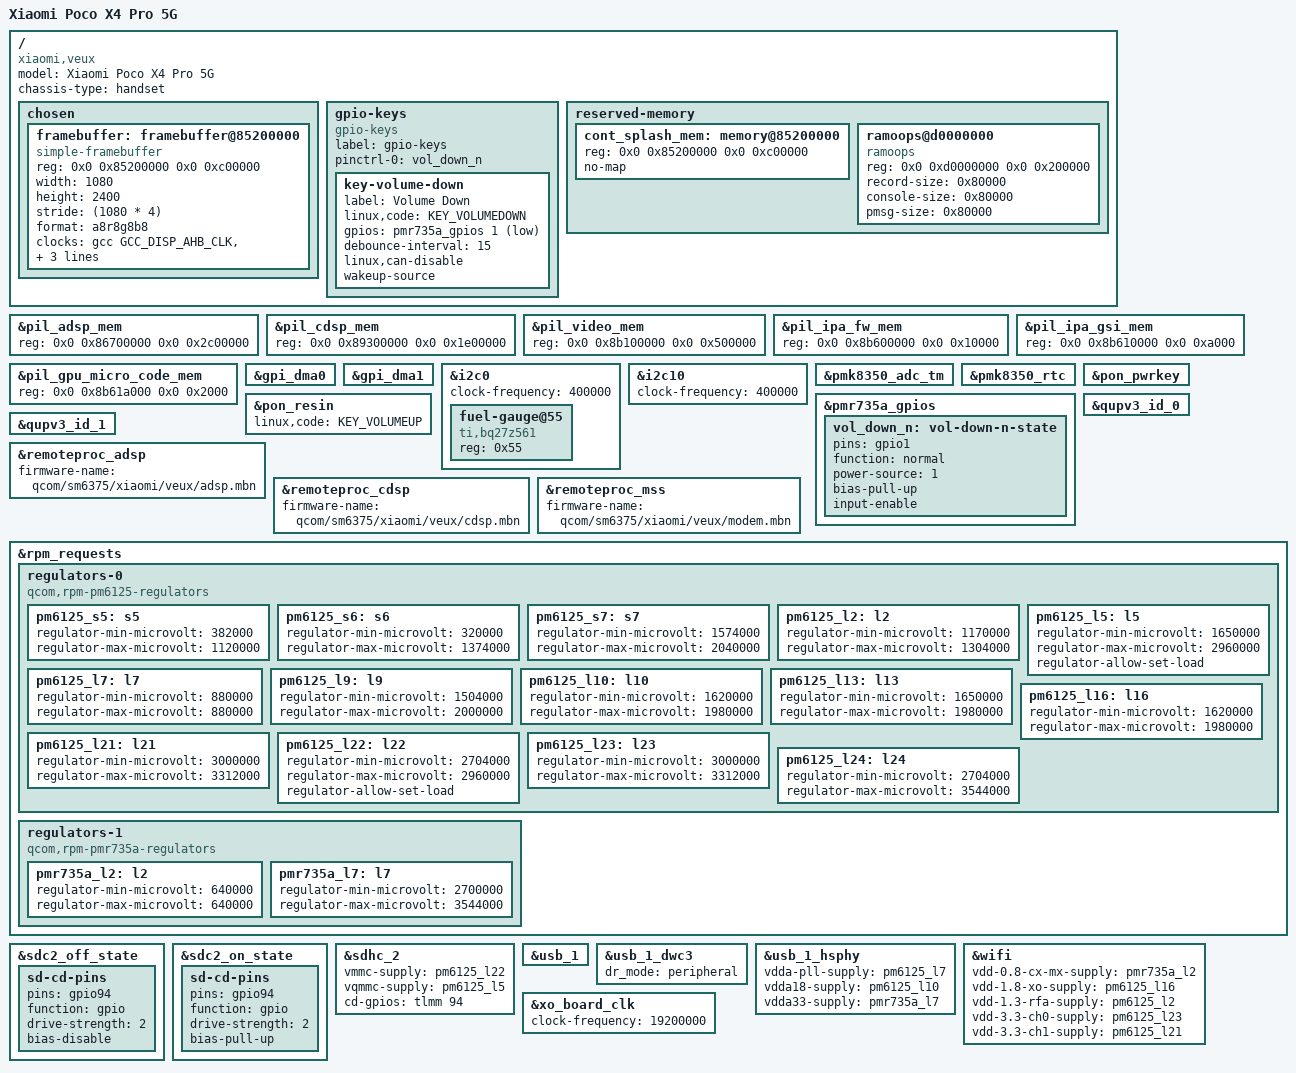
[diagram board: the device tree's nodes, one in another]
// SPDX-License-Identifier: BSD-3-Clause
/*
 * Copyright (c) 2026, Xiaomi Poco X4 Pro 5G (veux) Mainline Port
 */

/dts-v1/;

/* PMK8350 is configured to use SID6 instead of 0 */
#define PMK8350_SID 6

#include <dt-bindings/gpio/gpio.h>
#include <dt-bindings/input/linux-event-codes.h>
#include "sm6375.dtsi"
#include "pm6125.dtsi"
#include "pmk8350.dtsi"
#include "pmr735a.dtsi"

/* PM6125 PON is used and we can't have duplicate labels */
/delete-node/ &pmk8350_pon;

/ {
	model = "Xiaomi Poco X4 Pro 5G";
	compatible = "xiaomi,veux", "qcom,sm6375";
	chassis-type = "handset";

	chosen {
		#address-cells = <2>;
		#size-cells = <2>;
		ranges;

		framebuffer: framebuffer@85200000 {
			compatible = "simple-framebuffer";
			reg = <0x0 0x85200000 0x0 0xc00000>;

			width = <1080>;
			height = <2400>;
			stride = <(1080 * 4)>;
			format = "a8r8g8b8";
			clocks = <&gcc GCC_DISP_AHB_CLK>,
				 <&gcc GCC_DISP_HF_AXI_CLK>,
				 <&gcc GCC_DISP_THROTTLE_CORE_CLK>,
				 <&gcc GCC_DISP_GPLL0_DIV_CLK_SRC>;
		};
	};

	gpio-keys {
		compatible = "gpio-keys";
		label = "gpio-keys";

		pinctrl-0 = <&vol_down_n>;
		pinctrl-names = "default";

		key-volume-down {
			label = "Volume Down";
			linux,code = <KEY_VOLUMEDOWN>;
			gpios = <&pmr735a_gpios 1 GPIO_ACTIVE_LOW>;
			debounce-interval = <15>;
			linux,can-disable;
			wakeup-source;
		};
	};

	reserved-memory {
		cont_splash_mem: memory@85200000 {
			reg = <0x0 0x85200000 0x0 0xc00000>;
			no-map;
		};

		ramoops@d0000000 {
			compatible = "ramoops";
			reg = <0x0 0xd0000000 0x0 0x200000>;
			record-size = <0x80000>;
			console-size = <0x80000>;
			pmsg-size = <0x80000>;
		};
	};
};

&pil_adsp_mem {
	reg = <0x0 0x86700000 0x0 0x2c00000>;
};

&pil_cdsp_mem {
	reg = <0x0 0x89300000 0x0 0x1e00000>;
};

&pil_video_mem {
	reg = <0x0 0x8b100000 0x0 0x500000>;
};

&pil_ipa_fw_mem {
	reg = <0x0 0x8b600000 0x0 0x10000>;
};

&pil_ipa_gsi_mem {
	reg = <0x0 0x8b610000 0x0 0xa000>;
};

&pil_gpu_micro_code_mem {
	reg = <0x0 0x8b61a000 0x0 0x2000>;
};

&gpi_dma0 {
	status = "okay";
};

&gpi_dma1 {
	status = "okay";
};

&i2c0 {
	clock-frequency = <400000>;
	status = "okay";

	fuel-gauge@55 {
		compatible = "ti,bq27z561";
		reg = <0x55>;
	};
};

&i2c10 {
	clock-frequency = <400000>;
	status = "okay";
};

&pmk8350_adc_tm {
	status = "okay";
};

&pmk8350_rtc {
	status = "okay";
};

&pmr735a_gpios {
	vol_down_n: vol-down-n-state {
		pins = "gpio1";
		function = "normal";
		power-source = <1>;
		bias-pull-up;
		input-enable;
	};
};

&pon_pwrkey {
	status = "okay";
};

&pon_resin {
	linux,code = <KEY_VOLUMEUP>;
	status = "okay";
};

&qupv3_id_0 {
	status = "okay";
};

&qupv3_id_1 {
	status = "okay";
};

&remoteproc_adsp {
	firmware-name = "qcom/sm6375/xiaomi/veux/adsp.mbn";
	status = "okay";
};

&remoteproc_cdsp {
	firmware-name = "qcom/sm6375/xiaomi/veux/cdsp.mbn";
	status = "okay";
};

&remoteproc_mss {
	firmware-name = "qcom/sm6375/xiaomi/veux/modem.mbn";
	status = "okay";
};

&rpm_requests {
	regulators-0 {
		compatible = "qcom,rpm-pm6125-regulators";

		pm6125_s5: s5 {
			regulator-min-microvolt = <382000>;
			regulator-max-microvolt = <1120000>;
		};

		pm6125_s6: s6 {
			regulator-min-microvolt = <320000>;
			regulator-max-microvolt = <1374000>;
		};

		pm6125_s7: s7 {
			regulator-min-microvolt = <1574000>;
			regulator-max-microvolt = <2040000>;
		};

		pm6125_l2: l2 {
			regulator-min-microvolt = <1170000>;
			regulator-max-microvolt = <1304000>;
		};

		pm6125_l5: l5 {
			regulator-min-microvolt = <1650000>;
			regulator-max-microvolt = <2960000>;
			regulator-allow-set-load;
		};

		pm6125_l7: l7 {
			regulator-min-microvolt = <880000>;
			regulator-max-microvolt = <880000>;
		};

		pm6125_l9: l9 {
			regulator-min-microvolt = <1504000>;
			regulator-max-microvolt = <2000000>;
		};

		pm6125_l10: l10 {
			regulator-min-microvolt = <1620000>;
			regulator-max-microvolt = <1980000>;
		};

		pm6125_l13: l13 {
			regulator-min-microvolt = <1650000>;
			regulator-max-microvolt = <1980000>;
		};

		pm6125_l16: l16 {
			regulator-min-microvolt = <1620000>;
			regulator-max-microvolt = <1980000>;
		};

		pm6125_l21: l21 {
			regulator-min-microvolt = <3000000>;
			regulator-max-microvolt = <3312000>;
		};

		pm6125_l22: l22 {
			regulator-min-microvolt = <2704000>;
			regulator-max-microvolt = <2960000>;
			regulator-allow-set-load;
		};

		pm6125_l23: l23 {
			regulator-min-microvolt = <3000000>;
			regulator-max-microvolt = <3312000>;
		};

		pm6125_l24: l24 {
			regulator-min-microvolt = <2704000>;
			regulator-max-microvolt = <3544000>;
		};
	};

	regulators-1 {
		compatible = "qcom,rpm-pmr735a-regulators";

		pmr735a_l2: l2 {
			regulator-min-microvolt = <640000>;
			regulator-max-microvolt = <640000>;
		};

		pmr735a_l7: l7 {
			regulator-min-microvolt = <2700000>;
			regulator-max-microvolt = <3544000>;
		};
	};
};

&sdc2_off_state {
	sd-cd-pins {
		pins = "gpio94";
		function = "gpio";
		drive-strength = <2>;
		bias-disable;
	};
};

&sdc2_on_state {
	sd-cd-pins {
		pins = "gpio94";
		function = "gpio";
		drive-strength = <2>;
		bias-pull-up;
	};
};

&sdhc_2 {
	status = "okay";

	vmmc-supply = <&pm6125_l22>;
	vqmmc-supply = <&pm6125_l5>;

	cd-gpios = <&tlmm 94 GPIO_ACTIVE_HIGH>;
};

&usb_1 {
	status = "okay";
};

&usb_1_dwc3 {
	dr_mode = "peripheral";
};

&usb_1_hsphy {
	vdda-pll-supply = <&pm6125_l7>;
	vdda18-supply = <&pm6125_l10>;
	vdda33-supply = <&pmr735a_l7>;
	status = "okay";
};

&wifi {
	vdd-0.8-cx-mx-supply = <&pmr735a_l2>;
	vdd-1.8-xo-supply = <&pm6125_l16>;
	vdd-1.3-rfa-supply = <&pm6125_l2>;
	vdd-3.3-ch0-supply = <&pm6125_l23>;
	vdd-3.3-ch1-supply = <&pm6125_l21>;
	status = "okay";
};

&xo_board_clk {
	clock-frequency = <19200000>;
};
